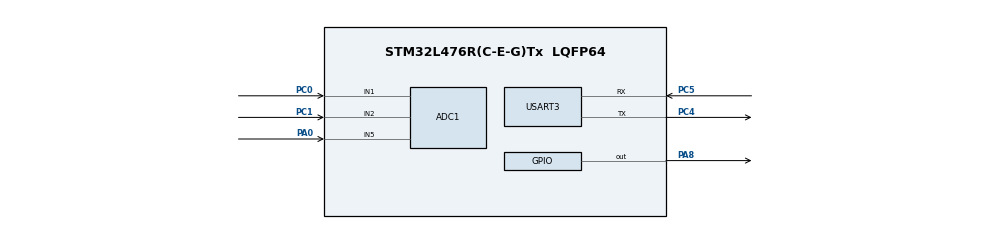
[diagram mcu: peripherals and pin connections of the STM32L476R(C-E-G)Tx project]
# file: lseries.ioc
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ADC1.Channel-0\#ChannelRegularConversion=ADC_CHANNEL_1
ADC1.Channel-1\#ChannelRegularConversion=ADC_CHANNEL_2
ADC1.Channel-2\#ChannelRegularConversion=ADC_CHANNEL_5
ADC1.ContinuousConvMode=ENABLE
ADC1.DMAContinuousRequests=ENABLE
ADC1.EOCSelection=ADC_EOC_SEQ_CONV
ADC1.NbrOfConversion=3
ADC1.NbrOfConversionFlag=1
ADC1.OffsetNumber-0\#ChannelRegularConversion=ADC_OFFSET_NONE
ADC1.OffsetNumber-1\#ChannelRegularConversion=ADC_OFFSET_NONE
ADC1.OffsetNumber-2\#ChannelRegularConversion=ADC_OFFSET_NONE
ADC1.Rank-0\#ChannelRegularConversion=1
ADC1.Rank-1\#ChannelRegularConversion=2
ADC1.Rank-2\#ChannelRegularConversion=3
ADC1.SamplingTime-0\#ChannelRegularConversion=ADC_SAMPLETIME_640CYCLES_5
ADC1.SamplingTime-1\#ChannelRegularConversion=ADC_SAMPLETIME_640CYCLES_5
ADC1.SamplingTime-2\#ChannelRegularConversion=ADC_SAMPLETIME_640CYCLES_5
ADC1.master=1
Dma.ADC1.0.Direction=DMA_PERIPH_TO_MEMORY
Dma.ADC1.0.Instance=DMA1_Channel1
Dma.ADC1.0.MemDataAlignment=DMA_MDATAALIGN_HALFWORD
Dma.ADC1.0.MemInc=DMA_MINC_ENABLE
Dma.ADC1.0.Mode=DMA_CIRCULAR
Dma.ADC1.0.PeriphDataAlignment=DMA_PDATAALIGN_HALFWORD
Dma.ADC1.0.PeriphInc=DMA_PINC_DISABLE
Dma.ADC1.0.Priority=DMA_PRIORITY_HIGH
Dma.Request0=ADC1
Mcu.Family=STM32L4
Mcu.Name=STM32L476R(C-E-G)Tx
Mcu.Package=LQFP64
NVIC.DMA1_Channel1_IRQn=true\:0\:0\:false\:false\:true\:false\:true\:true
NVIC.PriorityGroup=NVIC_PRIORITYGROUP_4
PA0.Signal=ADCx_IN5
PA13\ (JTMS-SWDIO).Mode=Serial_Wire
PA13\ (JTMS-SWDIO).Signal=SYS_JTMS-SWDIO
PA14\ (JTCK-SWCLK).Mode=Serial_Wire
PA14\ (JTCK-SWCLK).Signal=SYS_JTCK-SWCLK
PA8.Signal=GPIO_Output
PC0.Signal=ADCx_IN1
PC1.Signal=ADCx_IN2
PC4.Mode=Asynchronous
PC4.Signal=USART3_TX
PC5.Mode=Asynchronous
PC5.Signal=USART3_RX
PH0-OSC_IN\ (PH0).Mode=HSE-External-Oscillator
PH0-OSC_IN\ (PH0).Signal=RCC_OSC_IN
PH1-OSC_OUT\ (PH1).Mode=HSE-External-Oscillator
PH1-OSC_OUT\ (PH1).Signal=RCC_OSC_OUT
ProjectManager.HeapSize=0x200
ProjectManager.StackSize=0x400
ProjectManager.TargetToolchain=STM32CubeIDE
RCC.HSE_VALUE=8000000
RCC.HSI_VALUE=16000000
RCC.LSE_VALUE=32768
RCC.MSI_VALUE=4000000
RCC.VCOOutputFreq_Value=32000000
SH.ADCx_IN1.0=ADC1_IN1,IN1-Single-Ended
SH.ADCx_IN2.0=ADC1_IN2,IN2-Single-Ended
SH.ADCx_IN5.0=ADC1_IN5,IN5-Single-Ended
USART3.VirtualMode-Asynchronous=VM_ASYNC
board=custom

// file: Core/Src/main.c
/* USER CODE BEGIN Header */
/**
  ******************************************************************************
  * @file           : main.c
  * @brief          : Main program body
  ******************************************************************************
  * @attention
  *
  * Copyright (c) 2026 STMicroelectronics.
  * All rights reserved.
  *
  * This software is licensed under terms that can be found in the LICENSE file
  * in the root directory of this software component.
  * If no LICENSE file comes with this software, it is provided AS-IS.
  *
  ******************************************************************************
  */
/* USER CODE END Header */
#include "main.h"
/* USER CODE BEGIN Includes */
#include <stdio.h>
#include <string.h>
#include <stdlib.h>
/* USER CODE END Includes */

ADC_HandleTypeDef hadc1;
DMA_HandleTypeDef hdma_adc1;

UART_HandleTypeDef huart3;

/* USER CODE BEGIN PV */
volatile uint16_t adc_buffer[3]; // [0]=PC0, [1]=PC1, [2]=PA0
/* USER CODE END PV */
int32_t zero_offset_mv = 2500; // Default startup value
uint32_t data_index = 0;

void SystemClock_Config(void);
static void MX_GPIO_Init(void);
static void MX_DMA_Init(void);
static void MX_ADC1_Init(void);
static void MX_USART3_UART_Init(void);

int main(void)
{

  /* MCU Configuration--------------------------------------------------------*/

  /* Reset of all peripherals, Initializes the Flash interface and the Systick. */
  HAL_Init();

  /* Configure the system clock */
  SystemClock_Config();

  /* Initialize all configured peripherals */
  MX_GPIO_Init();
  MX_DMA_Init();
  MX_ADC1_Init();
  MX_USART3_UART_Init();
  /* USER CODE BEGIN 2 */
  /* Inside main() -> After MX_DMA_Init() and MX_ADC1_Init() -> In USER CODE BEGIN 2 */
  HAL_ADC_Start_DMA(&hadc1, (uint32_t*)adc_buffer, 3);
  HAL_Delay(500); // Wait for ADC to stabilize

  // Perform one-time calibration at startup (assuming load is already connected)
  int32_t sum = 0;
  for(int i = 0; i < 100; i++) {
      sum += (adc_buffer[2] * 3300) / 4095;
      HAL_Delay(10);
  }
  zero_offset_mv = sum / 100; // This captures the "Baseline" (e.g., your 1.2A load value)

  /* Inside while(1) -> Replace your existing loop content */
  while (1)
  {
	  HAL_GPIO_WritePin(GPIOA, GPIO_PIN_8, GPIO_PIN_RESET);
	        HAL_Delay(100);
      // 1. Raw ADC to mV
      uint32_t raw_mv_0 = (adc_buffer[0] * 3300) / 4095;
      uint32_t raw_mv_1 = (adc_buffer[1] * 3300) / 4095;
      uint32_t raw_mv_2 = (adc_buffer[2] * 3300) / 4095;

      // 2. Voltage Scaling
      float v_val = (float)(raw_mv_0 * 76) / 10000.0f;
      float cap_val = (float)(raw_mv_1 * 74) / 10000.0f;

      // 3. Current Calculation (Relative to baseline)
      // Formula: Current = 1.2A + ((Offset_mV - Current_mV) / Sensitivity)
      // Sensitivity is 100mV/A for ACS712-20A
      int32_t diff_mv = zero_offset_mv - (int32_t)raw_mv_2;
      float current_A = 1.2f + ((float)diff_mv / 100.0f);

      if (current_A < 0.05f) current_A = 0.00f;

      // 4. Send Data
      // 4. Send Data: ADC0, ADC1, ADC2, V_Val, Cap_Val, I_Val
            char msg[128];
            int len = sprintf(msg, "%u,%u,%u,%.2f,%.2f,%.3f\r\n",
                        adc_buffer[0], adc_buffer[1], adc_buffer[2],
                        v_val, cap_val, current_A);

            HAL_UART_Transmit(&huart3, (uint8_t*)msg, len, 100);
            HAL_GPIO_WritePin(GPIOA, GPIO_PIN_8, GPIO_PIN_SET);
            HAL_Delay(500);
  }
    /* USER CODE END WHILE */
  /* USER CODE END 3 */
}

void SystemClock_Config(void)
{
  RCC_OscInitTypeDef RCC_OscInitStruct = {0};
  RCC_ClkInitTypeDef RCC_ClkInitStruct = {0};

  /** Configure the main internal regulator output voltage
  */
  if (HAL_PWREx_ControlVoltageScaling(PWR_REGULATOR_VOLTAGE_SCALE1) != HAL_OK)
  {
    Error_Handler();
  }

  /** Initializes the RCC Oscillators according to the specified parameters
  * in the RCC_OscInitTypeDef structure.
  */
  RCC_OscInitStruct.OscillatorType = RCC_OSCILLATORTYPE_MSI;
  RCC_OscInitStruct.MSIState = RCC_MSI_ON;
  RCC_OscInitStruct.MSICalibrationValue = 0;
  RCC_OscInitStruct.MSIClockRange = RCC_MSIRANGE_6;
  RCC_OscInitStruct.PLL.PLLState = RCC_PLL_NONE;
  if (HAL_RCC_OscConfig(&RCC_OscInitStruct) != HAL_OK)
  {
    Error_Handler();
  }

  /** Initializes the CPU, AHB and APB buses clocks
  */
  RCC_ClkInitStruct.ClockType = RCC_CLOCKTYPE_HCLK|RCC_CLOCKTYPE_SYSCLK
                              |RCC_CLOCKTYPE_PCLK1|RCC_CLOCKTYPE_PCLK2;
  RCC_ClkInitStruct.SYSCLKSource = RCC_SYSCLKSOURCE_MSI;
  RCC_ClkInitStruct.AHBCLKDivider = RCC_SYSCLK_DIV1;
  RCC_ClkInitStruct.APB1CLKDivider = RCC_HCLK_DIV1;
  RCC_ClkInitStruct.APB2CLKDivider = RCC_HCLK_DIV1;

  if (HAL_RCC_ClockConfig(&RCC_ClkInitStruct, FLASH_LATENCY_0) != HAL_OK)
  {
    Error_Handler();
  }
}

static void MX_ADC1_Init(void)
{

  ADC_MultiModeTypeDef multimode = {0};
  ADC_ChannelConfTypeDef sConfig = {0};

  /** Common config
  */
  hadc1.Instance = ADC1;
  hadc1.Init.ClockPrescaler = ADC_CLOCK_ASYNC_DIV1;
  hadc1.Init.Resolution = ADC_RESOLUTION_12B;
  hadc1.Init.DataAlign = ADC_DATAALIGN_RIGHT;
  hadc1.Init.ScanConvMode = ADC_SCAN_ENABLE;
  hadc1.Init.EOCSelection = ADC_EOC_SEQ_CONV;
  hadc1.Init.LowPowerAutoWait = DISABLE;
  hadc1.Init.ContinuousConvMode = ENABLE;
  hadc1.Init.NbrOfConversion = 3;
  hadc1.Init.DiscontinuousConvMode = DISABLE;
  hadc1.Init.ExternalTrigConv = ADC_SOFTWARE_START;
  hadc1.Init.ExternalTrigConvEdge = ADC_EXTERNALTRIGCONVEDGE_NONE;
  hadc1.Init.DMAContinuousRequests = ENABLE;
  hadc1.Init.Overrun = ADC_OVR_DATA_PRESERVED;
  hadc1.Init.OversamplingMode = DISABLE;
  if (HAL_ADC_Init(&hadc1) != HAL_OK)
  {
    Error_Handler();
  }

  /** Configure the ADC multi-mode
  */
  multimode.Mode = ADC_MODE_INDEPENDENT;
  if (HAL_ADCEx_MultiModeConfigChannel(&hadc1, &multimode) != HAL_OK)
  {
    Error_Handler();
  }

  /** Configure Regular Channel
  */
  sConfig.Channel = ADC_CHANNEL_1;
  sConfig.Rank = ADC_REGULAR_RANK_1;
  sConfig.SamplingTime = ADC_SAMPLETIME_640CYCLES_5;
  sConfig.SingleDiff = ADC_SINGLE_ENDED;
  sConfig.OffsetNumber = ADC_OFFSET_NONE;
  sConfig.Offset = 0;
  if (HAL_ADC_ConfigChannel(&hadc1, &sConfig) != HAL_OK)
  {
    Error_Handler();
  }

  /** Configure Regular Channel
  */
  sConfig.Channel = ADC_CHANNEL_2;
  sConfig.Rank = ADC_REGULAR_RANK_2;
  if (HAL_ADC_ConfigChannel(&hadc1, &sConfig) != HAL_OK)
  {
    Error_Handler();
  }

  /** Configure Regular Channel
  */
  sConfig.Channel = ADC_CHANNEL_5;
  sConfig.Rank = ADC_REGULAR_RANK_3;
  if (HAL_ADC_ConfigChannel(&hadc1, &sConfig) != HAL_OK)
  {
    Error_Handler();
  }

}

static void MX_USART3_UART_Init(void)
{

  huart3.Instance = USART3;
  huart3.Init.BaudRate = 115200;
  huart3.Init.WordLength = UART_WORDLENGTH_8B;
  huart3.Init.StopBits = UART_STOPBITS_1;
  huart3.Init.Parity = UART_PARITY_NONE;
  huart3.Init.Mode = UART_MODE_TX_RX;
  huart3.Init.HwFlowCtl = UART_HWCONTROL_NONE;
  huart3.Init.OverSampling = UART_OVERSAMPLING_16;
  huart3.Init.OneBitSampling = UART_ONE_BIT_SAMPLE_DISABLE;
  huart3.AdvancedInit.AdvFeatureInit = UART_ADVFEATURE_NO_INIT;
  if (HAL_UART_Init(&huart3) != HAL_OK)
  {
    Error_Handler();
  }

}

static void MX_DMA_Init(void)
{

  /* DMA controller clock enable */
  __HAL_RCC_DMA1_CLK_ENABLE();

  /* DMA interrupt init */
  /* DMA1_Channel1_IRQn interrupt configuration */
  HAL_NVIC_SetPriority(DMA1_Channel1_IRQn, 0, 0);
  HAL_NVIC_EnableIRQ(DMA1_Channel1_IRQn);

}

static void MX_GPIO_Init(void)
{
  GPIO_InitTypeDef GPIO_InitStruct = {0};

  /* GPIO Ports Clock Enable */
  __HAL_RCC_GPIOH_CLK_ENABLE();
  __HAL_RCC_GPIOC_CLK_ENABLE();
  __HAL_RCC_GPIOA_CLK_ENABLE();

  /*Configure GPIO pin Output Level */
  HAL_GPIO_WritePin(GPIOA, GPIO_PIN_8, GPIO_PIN_RESET);

  /*Configure GPIO pin : PA8 */
  GPIO_InitStruct.Pin = GPIO_PIN_8;
  GPIO_InitStruct.Mode = GPIO_MODE_OUTPUT_PP;
  GPIO_InitStruct.Pull = GPIO_NOPULL;
  GPIO_InitStruct.Speed = GPIO_SPEED_FREQ_LOW;
  HAL_GPIO_Init(GPIOA, &GPIO_InitStruct);

}

void Error_Handler(void)
{
  __disable_irq();
  while (1)
  {
  }
}
